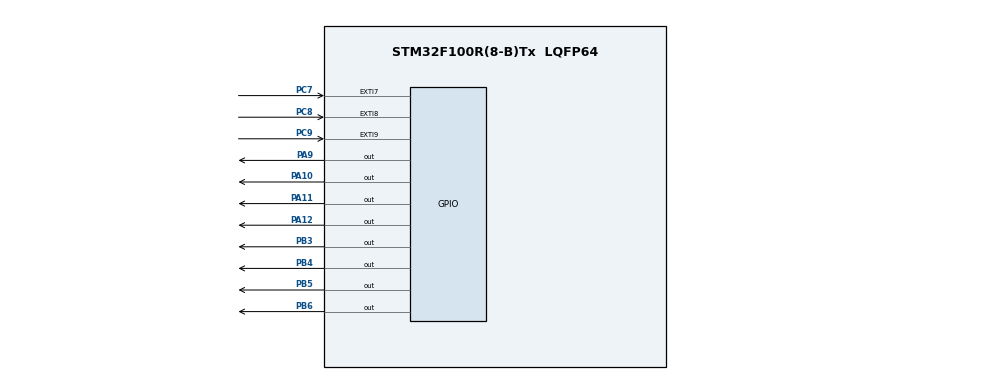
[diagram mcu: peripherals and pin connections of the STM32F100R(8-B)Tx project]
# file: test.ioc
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Mcu.Family=STM32F1
Mcu.Name=STM32F100R(8-B)Tx
Mcu.Package=LQFP64
NVIC.EXTI9_5_IRQn=true\:0\:0\:false\:false\:true\:true
NVIC.PriorityGroup=NVIC_PRIORITYGROUP_4
NVIC.TIM2_IRQn=true\:0\:0\:false\:false\:true\:true
PA10.Signal=GPIO_Output
PA11.Signal=GPIO_Output
PA12.Signal=GPIO_Output
PA13.Mode=Serial_Wire
PA13.Signal=SYS_JTMS-SWDIO
PA14.Mode=Serial_Wire
PA14.Signal=SYS_JTCK-SWCLK
PA9.Signal=GPIO_Output
PB3.Signal=GPIO_Output
PB4.Signal=GPIO_Output
PB5.Signal=GPIO_Output
PB6.Signal=GPIO_Output
PC7.GPIO_ModeDefaultEXTI=GPIO_MODE_IT_FALLING
PC7.GPIO_PuPd=GPIO_PULLDOWN
PC7.Signal=GPXTI7
PC8.GPIO_ModeDefaultEXTI=GPIO_MODE_IT_FALLING
PC8.GPIO_PuPd=GPIO_PULLDOWN
PC8.Signal=GPXTI8
PC9.GPIO_ModeDefaultEXTI=GPIO_MODE_IT_FALLING
PC9.GPIO_PuPd=GPIO_PULLDOWN
PC9.Signal=GPXTI9
ProjectManager.HeapSize=0x200
ProjectManager.StackSize=0x400
ProjectManager.TargetToolchain=MDK-ARM V5
RCC.APB1Freq_Value=8000000
RCC.APB2Freq_Value=8000000
TIM2.AutoReloadPreload=TIM_AUTORELOAD_PRELOAD_ENABLE
TIM2.Period=10
TIM2.Prescaler=8000
VP_TIM2_VS_ClockSourceINT.Mode=Internal
board=test

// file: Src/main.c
/**
  ******************************************************************************
  * File Name          : main.c
  * Description        : Main program body
  ******************************************************************************
  ** This notice applies to any and all portions of this file
  * that are not between comment pairs USER CODE BEGIN and
  * USER CODE END. Other portions of this file, whether
  * inserted by the user or by software development tools
  * are owned by their respective copyright owners.
  *
  * COPYRIGHT(c) 2019 STMicroelectronics
  *
  * Redistribution and use in source and binary forms, with or without modification,
  * are permitted provided that the following conditions are met:
  *   1. Redistributions of source code must retain the above copyright notice,
  *      this list of conditions and the following disclaimer.
  *   2. Redistributions in binary form must reproduce the above copyright notice,
  *      this list of conditions and the following disclaimer in the documentation
  *      and/or other materials provided with the distribution.
  *   3. Neither the name of STMicroelectronics nor the names of its contributors
  *      may be used to endorse or promote products derived from this software
  *      without specific prior written permission.
  *
  * THIS SOFTWARE IS PROVIDED BY THE COPYRIGHT HOLDERS AND CONTRIBUTORS "AS IS"
  * AND ANY EXPRESS OR IMPLIED WARRANTIES, INCLUDING, BUT NOT LIMITED TO, THE
  * IMPLIED WARRANTIES OF MERCHANTABILITY AND FITNESS FOR A PARTICULAR PURPOSE ARE
  * DISCLAIMED. IN NO EVENT SHALL THE COPYRIGHT HOLDER OR CONTRIBUTORS BE LIABLE
  * FOR ANY DIRECT, INDIRECT, INCIDENTAL, SPECIAL, EXEMPLARY, OR CONSEQUENTIAL
  * DAMAGES (INCLUDING, BUT NOT LIMITED TO, PROCUREMENT OF SUBSTITUTE GOODS OR
  * SERVICES; LOSS OF USE, DATA, OR PROFITS; OR BUSINESS INTERRUPTION) HOWEVER
  * CAUSED AND ON ANY THEORY OF LIABILITY, WHETHER IN CONTRACT, STRICT LIABILITY,
  * OR TORT (INCLUDING NEGLIGENCE OR OTHERWISE) ARISING IN ANY WAY OUT OF THE USE
  * OF THIS SOFTWARE, EVEN IF ADVISED OF THE POSSIBILITY OF SUCH DAMAGE.
  *
  ******************************************************************************
  */

#include "main.h"
#include "stm32f1xx_hal.h"

TIM_HandleTypeDef htim2;

/* USER CODE BEGIN PV */
/* Private variables ---------------------------------------------------------*/

/* USER CODE END PV */

void SystemClock_Config(void);
static void MX_GPIO_Init(void);
static void MX_TIM2_Init(void);

/* USER CODE BEGIN PFP */
/* Private function prototypes -----------------------------------------------*/

/* USER CODE END PFP */

int main(void)
{

  /* MCU Configuration----------------------------------------------------------*/

  /* Reset of all peripherals, Initializes the Flash interface and the Systick. */
  HAL_Init();

  /* Configure the system clock */
  SystemClock_Config();

  /* Initialize all configured peripherals */
  MX_GPIO_Init();
  MX_TIM2_Init();

  /* USER CODE BEGIN 2 */
  GPIOB->ODR = ~(0x08); //инициализация стартового значения регистра Output Data блока GPIOB, устанавливаем 0 на контакт подсоединенный к выходу ROW0

	HAL_TIM_Base_Start(&htim2);
	HAL_TIM_Base_Start_IT(&htim2);

  /* USER CODE END 2 */

  /* Infinite loop */
  while (1)
  {

  }

}

/** System Clock Configuration
*/
void SystemClock_Config(void)
{

  RCC_OscInitTypeDef RCC_OscInitStruct;
  RCC_ClkInitTypeDef RCC_ClkInitStruct;

    /**Initializes the CPU, AHB and APB busses clocks
    */
  RCC_OscInitStruct.OscillatorType = RCC_OSCILLATORTYPE_HSI;
  RCC_OscInitStruct.HSIState = RCC_HSI_ON;
  RCC_OscInitStruct.HSICalibrationValue = 16;
  RCC_OscInitStruct.PLL.PLLState = RCC_PLL_NONE;
  if (HAL_RCC_OscConfig(&RCC_OscInitStruct) != HAL_OK)
  {
    _Error_Handler(__FILE__, __LINE__);
  }

    /**Initializes the CPU, AHB and APB busses clocks
    */
  RCC_ClkInitStruct.ClockType = RCC_CLOCKTYPE_HCLK|RCC_CLOCKTYPE_SYSCLK
                              |RCC_CLOCKTYPE_PCLK1|RCC_CLOCKTYPE_PCLK2;
  RCC_ClkInitStruct.SYSCLKSource = RCC_SYSCLKSOURCE_HSI;
  RCC_ClkInitStruct.AHBCLKDivider = RCC_SYSCLK_DIV1;
  RCC_ClkInitStruct.APB1CLKDivider = RCC_HCLK_DIV1;
  RCC_ClkInitStruct.APB2CLKDivider = RCC_HCLK_DIV1;

  if (HAL_RCC_ClockConfig(&RCC_ClkInitStruct, FLASH_LATENCY_0) != HAL_OK)
  {
    _Error_Handler(__FILE__, __LINE__);
  }

    /**Configure the Systick interrupt time
    */
  HAL_SYSTICK_Config(HAL_RCC_GetHCLKFreq()/1000);

    /**Configure the Systick
    */
  HAL_SYSTICK_CLKSourceConfig(SYSTICK_CLKSOURCE_HCLK);

  /* SysTick_IRQn interrupt configuration */
  HAL_NVIC_SetPriority(SysTick_IRQn, 0, 0);
}

/* TIM2 init function */
static void MX_TIM2_Init(void)
{

  TIM_ClockConfigTypeDef sClockSourceConfig;
  TIM_MasterConfigTypeDef sMasterConfig;

  htim2.Instance = TIM2;
  htim2.Init.Prescaler = 8000;
  htim2.Init.CounterMode = TIM_COUNTERMODE_UP;
  htim2.Init.Period = 10;
  htim2.Init.ClockDivision = TIM_CLOCKDIVISION_DIV1;
  htim2.Init.AutoReloadPreload = TIM_AUTORELOAD_PRELOAD_ENABLE;
  if (HAL_TIM_Base_Init(&htim2) != HAL_OK)
  {
    _Error_Handler(__FILE__, __LINE__);
  }

  sClockSourceConfig.ClockSource = TIM_CLOCKSOURCE_INTERNAL;
  if (HAL_TIM_ConfigClockSource(&htim2, &sClockSourceConfig) != HAL_OK)
  {
    _Error_Handler(__FILE__, __LINE__);
  }

  sMasterConfig.MasterOutputTrigger = TIM_TRGO_RESET;
  sMasterConfig.MasterSlaveMode = TIM_MASTERSLAVEMODE_DISABLE;
  if (HAL_TIMEx_MasterConfigSynchronization(&htim2, &sMasterConfig) != HAL_OK)
  {
    _Error_Handler(__FILE__, __LINE__);
  }

}

/** Configure pins as
        * Analog
        * Input
        * Output
        * EVENT_OUT
        * EXTI
*/
static void MX_GPIO_Init(void)
{

  GPIO_InitTypeDef GPIO_InitStruct;

  /* GPIO Ports Clock Enable */
  __HAL_RCC_GPIOC_CLK_ENABLE();
  __HAL_RCC_GPIOA_CLK_ENABLE();
  __HAL_RCC_GPIOB_CLK_ENABLE();

  /*Configure GPIO pin Output Level */
  HAL_GPIO_WritePin(GPIOA, GPIO_PIN_9|GPIO_PIN_10|GPIO_PIN_11|GPIO_PIN_12, GPIO_PIN_RESET);

  /*Configure GPIO pin Output Level */
  HAL_GPIO_WritePin(GPIOB, GPIO_PIN_3|GPIO_PIN_4|GPIO_PIN_5|GPIO_PIN_6, GPIO_PIN_RESET);

  /*Configure GPIO pins : PC7 PC8 PC9 */
  GPIO_InitStruct.Pin = GPIO_PIN_7|GPIO_PIN_8|GPIO_PIN_9;
  GPIO_InitStruct.Mode = GPIO_MODE_IT_FALLING;
  GPIO_InitStruct.Pull = GPIO_PULLDOWN;
  HAL_GPIO_Init(GPIOC, &GPIO_InitStruct);

  /*Configure GPIO pins : PA9 PA10 PA11 PA12 */
  GPIO_InitStruct.Pin = GPIO_PIN_9|GPIO_PIN_10|GPIO_PIN_11|GPIO_PIN_12;
  GPIO_InitStruct.Mode = GPIO_MODE_OUTPUT_PP;
  GPIO_InitStruct.Speed = GPIO_SPEED_FREQ_LOW;
  HAL_GPIO_Init(GPIOA, &GPIO_InitStruct);

  /*Configure GPIO pins : PB3 PB4 PB5 PB6 */
  GPIO_InitStruct.Pin = GPIO_PIN_3|GPIO_PIN_4|GPIO_PIN_5|GPIO_PIN_6;
  GPIO_InitStruct.Mode = GPIO_MODE_OUTPUT_PP;
  GPIO_InitStruct.Speed = GPIO_SPEED_FREQ_LOW;
  HAL_GPIO_Init(GPIOB, &GPIO_InitStruct);

  /* EXTI interrupt init*/
  HAL_NVIC_SetPriority(EXTI9_5_IRQn, 0, 0);
  HAL_NVIC_EnableIRQ(EXTI9_5_IRQn);

}

void _Error_Handler(char * file, int line)
{
  while(1)
  {
  }
}

/************************ (C) COPYRIGHT STMicroelectronics *****END OF FILE****/
